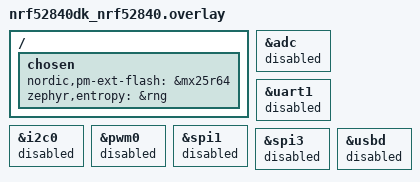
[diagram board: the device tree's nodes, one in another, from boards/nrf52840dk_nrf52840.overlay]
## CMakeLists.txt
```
#
# Copyright (c) 2023 Nordic Semiconductor ASA
#
# SPDX-License-Identifier: LicenseRef-Nordic-5-Clause
#

cmake_minimum_required(VERSION 3.20.0)

find_package(Zephyr HINTS $ENV{ZEPHYR_BASE})

project(matter-template)

# Enable GNU STD support and initialize the Matter Data Model.
include(${ZEPHYR_CONNECTEDHOMEIP_MODULE_DIR}/config/nrfconnect/app/enable-gnu-std.cmake)
include(${ZEPHYR_CONNECTEDHOMEIP_MODULE_DIR}/src/app/chip_data_model.cmake)

# NORDIC SDK APP START

# Include all source files that are located in the Matter common directory.
include(${ZEPHYR_NRF_MODULE_DIR}/samples/matter/common/cmake/source_common.cmake)

target_include_directories(app PRIVATE
    src
    ${CONFIG_NCS_SAMPLE_MATTER_ZAP_FILES_PATH}
)

target_sources(app PRIVATE
    src/app_task.cpp
    src/main.cpp
    src/temp_sensor_manager.cpp
    src/temperature_manager.cpp
    src/temperature_measurement/sensor.cpp
    src/zcl_callbacks.cpp
    ${ZEPHYR_NRF_MODULE_DIR}/samples/matter/common/src/binding/binding_handler.cpp
)

chip_configure_data_model(app
    INCLUDE_SERVER
    BYPASS_IDL
    GEN_DIR ${CONFIG_NCS_SAMPLE_MATTER_ZAP_FILES_PATH}/zap-generated
    ZAP_FILE ${CMAKE_CURRENT_SOURCE_DIR}/${CONFIG_NCS_SAMPLE_MATTER_ZAP_FILES_PATH}/thermostat.zap
)
# NORDIC SDK APP END
```

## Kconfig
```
#
# Copyright (c) 2023 Nordic Semiconductor
#
# SPDX-License-Identifier: LicenseRef-Nordic-5-Clause
#
mainmenu "Matter Thermostat sample application"

config THERMOSTAT_TEMPERATURE_STEP
	int "Defines a simulated temperature step. Use 0 for random"
	default 0
	help
	  A temperature step that defines differences between consecutive simulated temperature measurements. If set to 0, then the step is random.

config THERMOSTAT_SIMULATED_TEMPERATURE_MAX
	int "Maximum simulated temperature value"
	default 3000

config THERMOSTAT_SIMULATED_TEMPERATURE_MIN
	int "Minimum simulated temperature value"
	default 1500

config THERMOSTAT_SIMULATED_TEMPERATURE_CHANGE
	bool "Select to set the temperature to rise or fall"
	default y
	help
	  If set to true, the simulated temperature is rising. If set to false, the simulated temperature is falling.

# Enable Read Client functionality for all build configurations.
config CHIP_ENABLE_READ_CLIENT
	default y

# Sample configuration used for Thread networking
if NET_L2_OPENTHREAD

choice OPENTHREAD_NORDIC_LIBRARY_CONFIGURATION
	default OPENTHREAD_NORDIC_LIBRARY_MTD
endchoice

choice OPENTHREAD_DEVICE_TYPE
	default OPENTHREAD_MTD
endchoice

endif # NET_L2_OPENTHREAD

source "${ZEPHYR_CONNECTEDHOMEIP_MODULE_DIR}/config/nrfconnect/chip-module/Kconfig.features"
source "${ZEPHYR_CONNECTEDHOMEIP_MODULE_DIR}/config/nrfconnect/chip-module/Kconfig.defaults"
source "${ZEPHYR_NRF_MODULE_DIR}/samples/matter/common/src/Kconfig"
source "Kconfig.zephyr"
```

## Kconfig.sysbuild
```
#
# Copyright (c) 2023 Nordic Semiconductor ASA
#
# SPDX-License-Identifier: LicenseRef-Nordic-5-Clause
#

config WIFI_NRF70
	default y if BOARD_NRF7002DK

#### Radio core selection
config NRF_DEFAULT_IPC_RADIO
	default y

# Enable IEEE802.15.4 serialization to network core
# This config automatically pulls in the `overlay-802154.conf` in the ipc_radio image
config NETCORE_IPC_RADIO_IEEE802154
	default y if SOC_SERIES_NRF53X && !WIFI_NRF70

# Enable Bluetooth serialization to network core
# This config automatically pulls in the `overlay-bt_hci_ipc.conf` in the ipc_radio image
config NETCORE_IPC_RADIO_BT_HCI_IPC
	default y if SOC_SERIES_NRF53X

#### Bootloader
choice BOOTLOADER
	default BOOTLOADER_MCUBOOT
endchoice

if BOOTLOADER_MCUBOOT

#### DFU multi-image support
config DFU_MULTI_IMAGE_PACKAGE_BUILD
	default y

config DFU_MULTI_IMAGE_PACKAGE_APP
	default y

config PM_EXTERNAL_FLASH_MCUBOOT_SECONDARY
	default y

#### DFU network core configuration
if SOC_SERIES_NRF53X

config MCUBOOT_UPDATEABLE_IMAGES
	default 2

choice MCUBOOT_MODE
	default MCUBOOT_MODE_OVERWRITE_ONLY
endchoice

choice BOOT_SIGNATURE_TYPE
	default BOOT_SIGNATURE_TYPE_RSA
endchoice

config SECURE_BOOT_NETCORE
	default y

config NETCORE_APP_UPDATE
	default y

config DFU_MULTI_IMAGE_PACKAGE_NET
	default y

endif # SOC_SERIES_NRF53X

if BOARD_NRF54L15DK_NRF54L15_CPUAPP_NS

# Disable checking the external drivers for NS build.
config PM_OVERRIDE_EXTERNAL_DRIVER_CHECK
	default y

# override the mcuboot pad size, because it is not set globally for NS build.
config PM_MCUBOOT_PAD
	default 0x800

endif # BOARD_NRF54L15DK_NRF54L15_CPUAPP_NS

endif # BOOTLOADER_MCUBOOT

#### Enable generating factory data
config MATTER_FACTORY_DATA_GENERATE
	default y

source "${ZEPHYR_BASE}/share/sysbuild/Kconfig"
```

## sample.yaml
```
sample:
  description: Matter Thermostat sample
  name: Matter Thermostat
tests:
  sample.matter.thermostat.debug:
    sysbuild: true
    build_only: true
    integration_platforms:
      - nrf52840dk/nrf52840
      - nrf5340dk/nrf5340/cpuapp
      - nrf7002dk/nrf5340/cpuapp
      - nrf54l15dk/nrf54l15/cpuapp
      - nrf54l15dk/nrf54l15/cpuapp/ns
    platform_allow: nrf52840dk/nrf52840 nrf5340dk/nrf5340/cpuapp nrf7002dk/nrf5340/cpuapp
      nrf54l15dk/nrf54l15/cpuapp nrf54l15dk/nrf54l15/cpuapp/ns
    tags: sysbuild ci_samples_matter
  sample.matter.thermostat.release:
    sysbuild: true
    build_only: true
    extra_args: FILE_SUFFIX=release
      SB_CONFIG_BOOTLOADER_MCUBOOT=y SB_CONFIG_PARTITION_MANAGER=y
    integration_platforms:
      - nrf52840dk/nrf52840
      - nrf5340dk/nrf5340/cpuapp
      - nrf7002dk/nrf5340/cpuapp
      - nrf54l15dk/nrf54l15/cpuapp
    platform_allow: nrf52840dk/nrf52840 nrf5340dk/nrf5340/cpuapp nrf7002dk/nrf5340/cpuapp
      nrf54l15dk/nrf54l15/cpuapp
    tags: sysbuild ci_samples_matter
  sample.matter.thermostat.lto:
    sysbuild: true
    build_only: true
    extra_args: CONFIG_LTO=y CONFIG_ISR_TABLES_LOCAL_DECLARATION=y
    integration_platforms:
      - nrf52840dk/nrf52840
      - nrf5340dk/nrf5340/cpuapp
      - nrf7002dk/nrf5340/cpuapp
      - nrf54l15dk/nrf54l15/cpuapp
    platform_allow: nrf52840dk/nrf52840 nrf5340dk/nrf5340/cpuapp nrf7002dk/nrf5340/cpuapp
      nrf54l15dk/nrf54l15/cpuapp
    tags: sysbuild ci_samples_matter
```

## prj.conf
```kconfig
#
# Copyright (c) 2023 Nordic Semiconductor ASA
#
# SPDX-License-Identifier: LicenseRef-Nordic-5-Clause
#

# This sample uses Kconfig.defaults to set options common for all
# samples. This file should contain only options specific for this sample
# or overrides of default values.

# Enable CHIP
CONFIG_CHIP=y
CONFIG_CHIP_PROJECT_CONFIG="src/chip_project_config.h"
# 32782 == 0x800e (example thermostat product)
CONFIG_CHIP_DEVICE_PRODUCT_ID=32782
CONFIG_STD_CPP17=y

# Enable Matter pairing automatically on application start.
CONFIG_CHIP_ENABLE_PAIRING_AUTOSTART=y

# Enable Matter extended announcement and increase duration to 1 hour.
CONFIG_CHIP_BLE_EXT_ADVERTISING=y
CONFIG_CHIP_BLE_ADVERTISING_DURATION=60

# Add support for LEDs and buttons on Nordic development kits
CONFIG_DK_LIBRARY=y

# Bluetooth Low Energy configuration
CONFIG_BT_DEVICE_NAME="MatterThermo"

# Other settings
CONFIG_THREAD_NAME=y
CONFIG_MPU_STACK_GUARD=y
CONFIG_RESET_ON_FATAL_ERROR=n
CONFIG_CHIP_LIB_SHELL=y
CONFIG_NCS_SAMPLE_MATTER_TEST_SHELL=y

# Disable NFC commissioning
CONFIG_CHIP_NFC_COMMISSIONING=y

# Reduce application size
CONFIG_USE_SEGGER_RTT=n

# Enable Factory Data feature
CONFIG_CHIP_FACTORY_DATA=y
CONFIG_CHIP_FACTORY_DATA_BUILD=y
```

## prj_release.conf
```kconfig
#
# Copyright (c) 2023 Nordic Semiconductor ASA
#
# SPDX-License-Identifier: LicenseRef-Nordic-5-Clause
#

# This sample uses Kconfig.defaults to set options common for all
# samples. This file should contain only options specific for this sample
# or overrides of default values.

# Enable CHIP
CONFIG_CHIP=y
CONFIG_CHIP_PROJECT_CONFIG="src/chip_project_config.h"
# 32782 == 0x800e (example thermostat product)
CONFIG_CHIP_DEVICE_PRODUCT_ID=32782
CONFIG_STD_CPP17=y

# Enable Matter pairing automatically on application start.
CONFIG_CHIP_ENABLE_PAIRING_AUTOSTART=y

# Enable Matter extended announcement and increase duration to 1 hour.
CONFIG_CHIP_BLE_EXT_ADVERTISING=y
CONFIG_CHIP_BLE_ADVERTISING_DURATION=60

# Add support for LEDs and buttons on Nordic development kits
CONFIG_DK_LIBRARY=y

# Bluetooth Low Energy configuration
CONFIG_BT_DEVICE_NAME="MatterThermo"

# Enable system reset on fatal error
CONFIG_RESET_ON_FATAL_ERROR=y

# Disable all debug features
CONFIG_USE_SEGGER_RTT=n
CONFIG_SHELL=n
CONFIG_OPENTHREAD_SHELL=n
CONFIG_CONSOLE=n
CONFIG_UART_CONSOLE=n
CONFIG_SERIAL=n
CONFIG_LOG=n
CONFIG_LOG_MODE_MINIMAL=n
CONFIG_ASSERT_VERBOSE=n
CONFIG_ASSERT_NO_FILE_INFO=y
CONFIG_PRINTK=n
CONFIG_PRINTK_SYNC=n
CONFIG_THREAD_NAME=n

# Disable NFC commissioning
CONFIG_CHIP_NFC_COMMISSIONING=n

# Enable Factory Data feature
CONFIG_CHIP_FACTORY_DATA=y
CONFIG_CHIP_FACTORY_DATA_BUILD=y

# Enable Watchdog
CONFIG_NCS_SAMPLE_MATTER_WATCHDOG=y
```

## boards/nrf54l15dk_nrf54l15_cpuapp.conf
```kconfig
#
# Copyright (c) 2024 Nordic Semiconductor ASA
#
# SPDX-License-Identifier: LicenseRef-Nordic-5-Clause
#

# Multirole is the only currently supported role by SoftDevice.
CONFIG_BT_LL_SOFTDEVICE_MULTIROLE=y

# nRF54L15 requires bigger stack sizes than nRF52/nRF53 families
CONFIG_CHIP_MALLOC_SYS_HEAP_SIZE=10240
CONFIG_MPSL_WORK_STACK_SIZE=2048

# Set the ZMS sector count to match the settings partition size that is 40 kB for this application.
CONFIG_SETTINGS_ZMS_SECTOR_COUNT=10

# Workaround required as Zephyr L2 implies usage of NVS backend for settings.
# It should be removed once the proper fix will be applied in Zephyr.
CONFIG_NVS=n
```

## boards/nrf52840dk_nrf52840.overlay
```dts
/* Copyright (c) 2023 Nordic Semiconductor ASA
 *
 * SPDX-License-Identifier: LicenseRef-Nordic-5-Clause
 */

 / {
	chosen {
		nordic,pm-ext-flash = &mx25r64;
	};
};


/ {
	/*
	* In some default configurations within the nRF Connect SDK,
	* e.g. on nRF52840, the chosen zephyr,entropy node is &cryptocell.
	* This devicetree overlay ensures that default is overridden wherever it
	* is set, as this application uses the RNG node for entropy exclusively.
	*/
	chosen {
		zephyr,entropy = &rng;
	};
};

/* Disable unused peripherals to reduce power consumption */
&adc {
	status = "disabled";
};
&uart1 {
	status = "disabled";
};
&i2c0 {
	status = "disabled";
};
&pwm0 {
	status = "disabled";
};
&spi1 {
	status = "disabled";
};
&spi3 {
	status = "disabled";
};
&usbd {
	status = "disabled";
};
```

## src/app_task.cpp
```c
/*
 * Copyright (c) 2023 Nordic Semiconductor ASA
 *
 * SPDX-License-Identifier: LicenseRef-Nordic-5-Clause
 */

#include "app_task.h"

#include "temp_sensor_manager.h"
#include "temperature_manager.h"

#include "app/matter_init.h"
#include "app/task_executor.h"

#ifdef CONFIG_CHIP_OTA_REQUESTOR
#include "dfu/ota/ota_util.h"
#endif

#include <app-common/zap-generated/attributes/Accessors.h>
#include <app/clusters/identify-server/identify-server.h>
#include <app/server/OnboardingCodesUtil.h>

#include <zephyr/logging/log.h>

LOG_MODULE_DECLARE(app, CONFIG_MATTER_LOG_LEVEL);

using namespace ::chip;
using namespace ::chip::app;
using namespace ::chip::DeviceLayer;

namespace
{
constexpr EndpointId kThermostatEndpointId = 1;

Identify sIdentify = { kThermostatEndpointId, AppTask::IdentifyStartHandler, AppTask::IdentifyStopHandler,
		       Clusters::Identify::IdentifyTypeEnum::kVisibleIndicator };

#define TEMPERATURE_BUTTON_MASK DK_BTN2_MSK
} // namespace

void AppTask::IdentifyStartHandler(Identify *)
{
	Nrf::PostTask(
		[] { Nrf::GetBoard().GetLED(Nrf::DeviceLeds::LED2).Blink(Nrf::LedConsts::kIdentifyBlinkRate_ms); });
}

void AppTask::IdentifyStopHandler(Identify *)
{
	Nrf::PostTask([] { Nrf::GetBoard().GetLED(Nrf::DeviceLeds::LED2).Set(false); });
}

void AppTask::ButtonEventHandler(Nrf::ButtonState state, Nrf::ButtonMask hasChanged)
{
	if (TEMPERATURE_BUTTON_MASK & hasChanged) {
		TemperatureButtonAction action = (TEMPERATURE_BUTTON_MASK & state) ? TemperatureButtonAction::Pushed :
										     TemperatureButtonAction::Released;
		Nrf::PostTask([action] { ThermostatHandler(action); });
	}
}

void AppTask::ThermostatHandler(const TemperatureButtonAction &action)
{
	if (action == TemperatureButtonAction::Pushed) {
		TemperatureManager::Instance().LogThermostatStatus();
	}
}

CHIP_ERROR AppTask::Init()
{
	/* Initialize Matter stack */
	ReturnErrorOnFailure(Nrf::Matter::PrepareServer(Nrf::Matter::InitData{ .mPostServerInitClbk = [] {
		CHIP_ERROR err = TempSensorManager::Instance().Init();
		if (err != CHIP_NO_ERROR) {
			LOG_ERR("TempSensorManager Init fail");
			return err;
		}
		err = TemperatureManager::Instance().Init();
		if (err != CHIP_NO_ERROR) {
			LOG_ERR("TempMgr Init fail");
		}
		return err;
	} }));

	if (!Nrf::GetBoard().Init(ButtonEventHandler)) {
		LOG_ERR("User interface initialization failed.");
		return CHIP_ERROR_INCORRECT_STATE;
	}

	/* Register Matter event handler that controls the connectivity status LED based on the captured Matter network
	 * state. */
	ReturnErrorOnFailure(Nrf::Matter::RegisterEventHandler(Nrf::Board::DefaultMatterEventHandler, 0));

	return Nrf::Matter::StartServer();
}

CHIP_ERROR AppTask::StartApp()
{
	ReturnErrorOnFailure(Init());

	while (true) {
		Nrf::DispatchNextTask();
	}

	return CHIP_NO_ERROR;
}
```

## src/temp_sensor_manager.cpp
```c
/*
 * Copyright (c) 2023 Nordic Semiconductor ASA
 *
 * SPDX-License-Identifier: LicenseRef-Nordic-5-Clause
 */

#include "temp_sensor_manager.h"
#include "app/task_executor.h"
#include "app_task.h"
#include "temperature_measurement/sensor.h"

LOG_MODULE_DECLARE(app, CONFIG_CHIP_APP_LOG_LEVEL);

using namespace chip;
using namespace chip::DeviceLayer;

static constexpr EndpointId kThermostatEndpoint = 1;

k_timer sSensorTimer;

CHIP_ERROR TempSensorManager::Init()
{
	k_timer_init(&sSensorTimer, &TempSensorManager::TimerEventHandler, nullptr);
	k_timer_start(&sSensorTimer, K_MSEC(kSensorTimerPeriodMs), K_MSEC(kSensorTimerPeriodMs));
	/* Workaround: Default null values are not correctly propagated from the zap file. Set it manually to make sure
	 * the starting value is cleared. */
	TempSensorManager::Instance().ClearLocalTemperature();
	TempSensorManager::Instance().ClearOutdoorTemperature();
	TemperatureSensor::Instance().FullMeasurement();

	return CHIP_NO_ERROR;
}

void TempSensorManager::TimerEventHandler(k_timer *timer)
{
	Nrf::PostTask([] { TempSensorManager::SensorTimerEventHandler(); });
}

/*
 *	This function is called when the timer is stopped and initiate temperature measurement.
 *	Depending ond object given to GetMeasurement() function thermostat will use true temeprature device or simulated
 *	values
 */

void TempSensorManager::SensorTimerEventHandler()
{
	TemperatureSensor::Instance().FullMeasurement();
}

void TempSensorManager::SetLocalTemperature(int16_t temperature)
{
	PlatformMgr().LockChipStack();
	app::Clusters::Thermostat::Attributes::LocalTemperature::Set(kThermostatEndpoint, temperature);
	PlatformMgr().UnlockChipStack();
}

void TempSensorManager::ClearLocalTemperature()
{
	PlatformMgr().LockChipStack();
	app::Clusters::Thermostat::Attributes::LocalTemperature::SetNull(kThermostatEndpoint);
	PlatformMgr().UnlockChipStack();
}

void TempSensorManager::SetOutdoorTemperature(int16_t temperature)
{
	PlatformMgr().LockChipStack();
	app::Clusters::Thermostat::Attributes::OutdoorTemperature::Set(kThermostatEndpoint, temperature);
	PlatformMgr().UnlockChipStack();
}

void TempSensorManager::ClearOutdoorTemperature()
{
	PlatformMgr().LockChipStack();
	app::Clusters::Thermostat::Attributes::OutdoorTemperature::SetNull(kThermostatEndpoint);
	PlatformMgr().UnlockChipStack();
}
```

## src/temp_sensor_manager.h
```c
/*
 * Copyright (c) 2023 Nordic Semiconductor ASA
 *
 * SPDX-License-Identifier: LicenseRef-Nordic-5-Clause
 */
#pragma once

#include <stdbool.h>
#include <stdint.h>

#include <app-common/zap-generated/attributes/Accessors.h>
#include <lib/core/CHIPError.h>

using namespace chip;

constexpr uint16_t kSensorTimerPeriodMs = 30000; /* 30s timer period*/

class TempSensorManager {
public:
	CHIP_ERROR Init();

	static TempSensorManager &Instance()
	{
		static TempSensorManager sTempSensorManager;
		return sTempSensorManager;
	};

	static void SetLocalTemperature(int16_t temperature);
	static void ClearLocalTemperature();
	static void SetOutdoorTemperature(int16_t temperature);
	static void ClearOutdoorTemperature();

private:
	static void TimerEventHandler(k_timer *timer);
	static void SensorTimerEventHandler();
};
```

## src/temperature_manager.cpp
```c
/*
 * Copyright (c) 2023 Nordic Semiconductor ASA
 *
 * SPDX-License-Identifier: LicenseRef-Nordic-5-Clause
 */

#include "temperature_manager.h"
#include "app_task.h"
#include <zephyr/logging/log.h>

LOG_MODULE_DECLARE(app, CONFIG_CHIP_APP_LOG_LEVEL);

using namespace chip;
using namespace ::chip::DeviceLayer;
using namespace ::chip::app::Clusters;

constexpr EndpointId kThermostatEndpoint = 1;

namespace
{

/* Convert and return only complete part of value to printable type */
uint8_t ReturnCompleteValue(int16_t Value)
{
	return static_cast<uint8_t>(Value / 100);
}

/* Converts and returns only reminder part of value to printable type.
 * This formula rounds reminder value to one significant figure
 */

uint8_t ReturnRemainderValue(int16_t Value)
{
	return static_cast<uint8_t>((Value % 100 + 5) / 10);
}

} // namespace

CHIP_ERROR TemperatureManager::Init()
{
	PlatformMgr().LockChipStack();
	Thermostat::Attributes::LocalTemperature::Get(kThermostatEndpoint, mLocalTempCelsius);
	Thermostat::Attributes::OutdoorTemperature::Get(kThermostatEndpoint, mOutdoorTempCelsius);
	Thermostat::Attributes::OccupiedCoolingSetpoint::Get(kThermostatEndpoint, &mCoolingCelsiusSetPoint);
	Thermostat::Attributes::OccupiedHeatingSetpoint::Get(kThermostatEndpoint, &mHeatingCelsiusSetPoint);
	Thermostat::Attributes::SystemMode::Get(kThermostatEndpoint, &mThermMode);
	PlatformMgr().UnlockChipStack();

	return CHIP_NO_ERROR;
}

void TemperatureManager::LogThermostatStatus()
{
	LOG_INF("Thermostat:");
	LOG_INF("	Mode - %d", static_cast<uint8_t>(mThermMode));
	if (!(GetLocalTemp().IsNull())) {
		int16_t tempValue = GetLocalTemp().Value();
		LOG_INF("	LocalTemperature - %d,%d'C", ReturnCompleteValue(tempValue),
			ReturnRemainderValue(tempValue));
	} else {
		LOG_INF("	LocalTemperature - No Value");
	}
	if (!(GetOutdoorTemp().IsNull())) {
		int16_t tempValue = GetOutdoorTemp().Value();
		LOG_INF("	OutdoorTemperature - %d,%d'C", ReturnCompleteValue(tempValue),
			ReturnRemainderValue(tempValue));
	} else {
		LOG_INF("	OutdoorTemperature - No Value");
	}
	LOG_INF("	HeatingSetpoint - %d,%d'C", ReturnCompleteValue(mHeatingCelsiusSetPoint),
		ReturnRemainderValue(mHeatingCelsiusSetPoint));
	LOG_INF("	CoolingSetpoint - %d,%d'C \n", ReturnCompleteValue(mCoolingCelsiusSetPoint),
		ReturnRemainderValue(mCoolingCelsiusSetPoint));
}

void TemperatureManager::AttributeChangeHandler(EndpointId endpointId, AttributeId attributeId, uint8_t *value,
						uint16_t size)
{
	switch (attributeId) {
	case Thermostat::Attributes::LocalTemperature::Id: {
		Thermostat::Attributes::LocalTemperature::Get(kThermostatEndpoint, mLocalTempCelsius);
	} break;

	case Thermostat::Attributes::OutdoorTemperature::Id: {
		Thermostat::Attributes::OutdoorTemperature::Get(kThermostatEndpoint, mOutdoorTempCelsius);
	} break;

	case Thermostat::Attributes::OccupiedCoolingSetpoint::Id: {
		mCoolingCelsiusSetPoint = *reinterpret_cast<int16_t *>(value);
		LOG_INF("Cooling TEMP: %d", mCoolingCelsiusSetPoint);
	} break;

	case Thermostat::Attributes::OccupiedHeatingSetpoint::Id: {
		mHeatingCelsiusSetPoint = *reinterpret_cast<int16_t *>(value);
		LOG_INF("Heating TEMP %d", mHeatingCelsiusSetPoint);
	} break;

	case Thermostat::Attributes::SystemMode::Id: {
		mThermMode = static_cast<app::Clusters::Thermostat::SystemModeEnum>(*value);
	} break;

	default: {
		LOG_INF("Unhandled thermostat attribute %x", attributeId);
		return;
	} break;
	}

	LogThermostatStatus();
}

app::DataModel::Nullable<int16_t> TemperatureManager::GetLocalTemp()
{
	return mLocalTempCelsius;
}

app::DataModel::Nullable<int16_t> TemperatureManager::GetOutdoorTemp()
{
	return mOutdoorTempCelsius;
}
```
